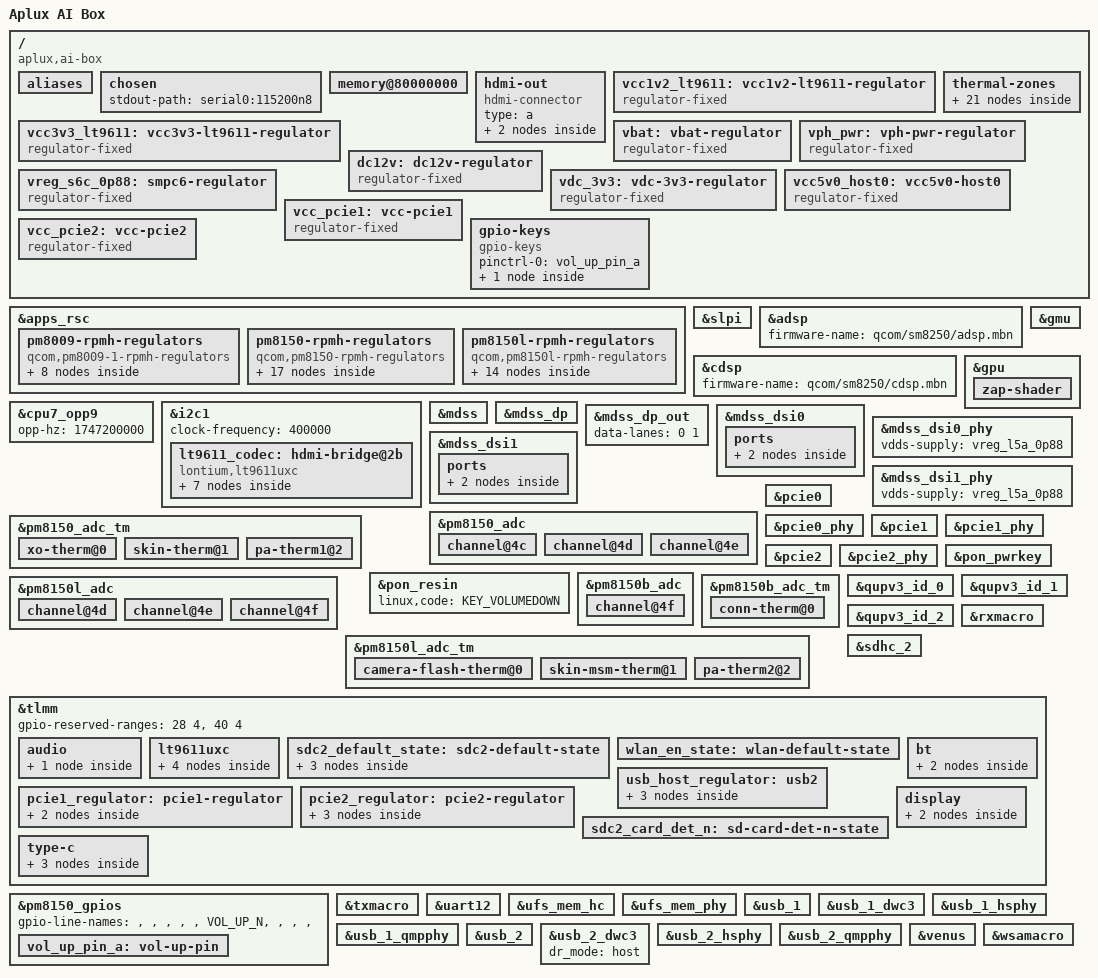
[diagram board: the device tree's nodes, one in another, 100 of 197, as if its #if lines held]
// SPDX-License-Identifier: BSD-3-Clause

/dts-v1/;

#include <dt-bindings/arm/qcom,ids.h>
#include <dt-bindings/regulator/qcom,rpmh-regulator.h>
#include <dt-bindings/phy/phy.h>
#include <dt-bindings/leds/common.h>
#include <dt-bindings/pinctrl/qcom,pmic-gpio.h>
#include <dt-bindings/sound/qcom,q6afe.h>
#include <dt-bindings/sound/qcom,q6asm.h>
#include <dt-bindings/gpio/gpio.h>
#include <dt-bindings/usb/pd.h>
#include "sm8250.dtsi"
#include "pm8150.dtsi"
#include "pm8150b.dtsi"
#include "pm8150l.dtsi"
#include "pm8009.dtsi"

#define ENABLE_HDMI 1

/ {
	model = "Aplux AI Box";
	compatible = "aplux,ai-box", "qcom,sm8250";
	qcom,msm-id = <QCOM_ID_SM8250 0x20001>;
	qcom,board-id = <QCOM_BOARD_ID(SBC, 1, 0) 0>;
	chassis-type = "embedded";

	aliases {
		serial0 = &uart12;
		serial1 = &uart6;
		sdhc2 = &sdhc_2;
	};

	chosen {
		stdout-path = "serial0:115200n8";
	};

#ifdef CONFIG_SYS_PROMPT
	memory@80000000 {
		device_type = "memory";
		reg = <0x00000000 0x80000000  0x00000000 0x3B800000>,   // 952MB
			  <0x00000000 0xC0000000  0x00000001 0xC0000000>;   // 7GB
	};
#endif

#if ENABLE_HDMI
	hdmi-out {
		compatible = "hdmi-connector";
		type = "a";

		port {
			hdmi_con: endpoint {
				remote-endpoint = <&lt9611_out>;
			};
		};
	};

	vcc1v2_lt9611: vcc1v2-lt9611-regulator {
		compatible = "regulator-fixed";
		regulator-name = "vcc1v2_lt9611";

		vin-supply = <&vdc_3v3>;
		regulator-min-microvolt = <1200000>;
		regulator-max-microvolt = <1200000>;

		gpio = <&tlmm 11 GPIO_ACTIVE_HIGH>; // verify
		enable-active-high;
		regulator-boot-on;
		regulator-always-on;

		pinctrl-names = "default";
		pinctrl-0 = <&lt9611_1v2_en>;
	};

	vcc3v3_lt9611: vcc3v3-lt9611-regulator {
		compatible = "regulator-fixed";
		regulator-name = "vcc3v3_lt9611";

		vin-supply = <&vdc_3v3>;
		regulator-min-microvolt = <3300000>;
		regulator-max-microvolt = <3300000>;

		gpio = <&tlmm 61 GPIO_ACTIVE_HIGH>; // verify
		enable-active-high;
		regulator-boot-on;
		regulator-always-on;

		pinctrl-names = "default";
		pinctrl-0 = <&lt9611_3v3_en>;
	};
#endif

	thermal-zones {
		camera-thermal {
			thermal-sensors = <&pm8150l_adc_tm 0>;

			trips {
				active-config0 {
					temperature = <125000>;
					hysteresis = <1000>;
					type = "passive";
				};
			};
		};

		conn-thermal {
			thermal-sensors = <&pm8150b_adc_tm 0>;

			trips {
				active-config0 {
					temperature = <125000>;
					hysteresis = <1000>;
					type = "passive";
				};
			};
		};

		mmw-pa1-thermal {
			thermal-sensors = <&pm8150_adc_tm 2>;

			trips {
				active-config0 {
					temperature = <125000>;
					hysteresis = <1000>;
					type = "passive";
				};
			};
		};

		mmw-pa2-thermal {
			thermal-sensors = <&pm8150l_adc_tm 2>;

			trips {
				active-config0 {
					temperature = <125000>;
					hysteresis = <1000>;
					type = "passive";
				};
			};
		};

		skin-msm-thermal {
			thermal-sensors = <&pm8150l_adc_tm 1>;

			trips {
				active-config0 {
					temperature = <125000>;
					hysteresis = <1000>;
					type = "passive";
				};
			};
		};

		skin-thermal {
			thermal-sensors = <&pm8150_adc_tm 1>;

			trips {
				active-config0 {
					temperature = <125000>;
					hysteresis = <1000>;
					type = "passive";
				};
			};
		};

		xo-thermal {
			thermal-sensors = <&pm8150_adc_tm 0>;

			trips {
				active-config0 {
					temperature = <125000>;
					hysteresis = <1000>;
					type = "passive";
				};
			};
		};
	};

	vbat: vbat-regulator {
		compatible = "regulator-fixed";
		regulator-name = "VBAT";
		vin-supply = <&vreg_l11c_3p3>;
		regulator-min-microvolt = <4200000>;
		regulator-max-microvolt = <4200000>;
		regulator-always-on;
	};

	vph_pwr: vph-pwr-regulator {
		compatible = "regulator-fixed";
		regulator-name = "vph_pwr";
		regulator-min-microvolt = <3700000>;
		regulator-max-microvolt = <3700000>;
	};
/*
	vreg_s4a_1p8: pm8150-s4 {
		compatible = "regulator-fixed";
		regulator-name = "vreg_s4a_1p8";

		regulator-min-microvolt = <1800000>;
		regulator-max-microvolt = <1800000>;

		regulator-always-on;
		regulator-boot-on;

		vin-supply = <&vph_pwr>;
	};
*/
	vreg_s6c_0p88: smpc6-regulator {
		compatible = "regulator-fixed";
		regulator-name = "vreg_s6c_0p88";

		regulator-min-microvolt = <880000>;
		regulator-max-microvolt = <880000>;
		regulator-always-on;
		vin-supply = <&vph_pwr>;
	};

	dc12v: dc12v-regulator {
		compatible = "regulator-fixed";
		regulator-name = "DC12V";
		regulator-min-microvolt = <12000000>;
		regulator-max-microvolt = <12000000>;
		regulator-always-on;
	};

	vdc_3v3: vdc-3v3-regulator {
		compatible = "regulator-fixed";
		regulator-name = "vdc_3v3";
		vin-supply = <&dc12v>;
		regulator-min-microvolt = <3300000>;
		regulator-max-microvolt = <3300000>;
		regulator-always-on;
	};

	vcc5v0_host0: vcc5v0-host0 {
		compatible = "regulator-fixed";
		regulator-name = "vcc5v0_host0";

		vin-supply = <&dc12v>;
		regulator-min-microvolt = <5000000>;
		regulator-max-microvolt = <5000000>;

		gpio = <&tlmm 117 GPIO_ACTIVE_HIGH>; // bsp
		enable-active-high;
		regulator-boot-on;
		regulator-always-on;

		pinctrl-names = "default";
		pinctrl-0 = <&usb_host_regulator>;
	};

	vcc_pcie1: vcc-pcie1 {
		compatible = "regulator-fixed";
		regulator-name = "vcc_pcie1";

		vin-supply = <&dc12v>;
		regulator-min-microvolt = <3300000>;
		regulator-max-microvolt = <3300000>;

		gpio = <&tlmm 6 GPIO_ACTIVE_HIGH>; // bsp
		enable-active-high;
		regulator-boot-on;
		regulator-always-on;

		pinctrl-names = "default";
		pinctrl-0 = <&pcie1_regulator>;
	};

	// RTL8111H
	vcc_pcie2: vcc-pcie2 {
		compatible = "regulator-fixed";
		regulator-name = "vcc_pcie2";

		vin-supply = <&dc12v>;
		regulator-min-microvolt = <3300000>;
		regulator-max-microvolt = <3300000>;

		gpio = <&tlmm 111 GPIO_ACTIVE_HIGH>; // verify
		enable-active-high;
		regulator-boot-on;
		regulator-always-on;

		pinctrl-names = "default";
		pinctrl-0 = <&pcie2_regulator>;
	};

	gpio-keys {
		compatible = "gpio-keys";
		pinctrl-0 = <&vol_up_pin_a>;

		key-vol-up {
			label = "Volume Up";
			linux,code = <KEY_VOLUMEUP>;
			gpios = <&pm8150_gpios 6 GPIO_ACTIVE_LOW>; // bsp
		};
	};
};

&apps_rsc {
	pm8009-rpmh-regulators {
		compatible = "qcom,pm8009-1-rpmh-regulators";
		qcom,pmic-id = "f";

		vdd-s1-supply = <&vph_pwr>;
		vdd-s2-supply = <&vph_pwr>;
		vdd-l2-supply = <&vreg_s8c_1p3>;
		vdd-l5-l6-supply = <&vreg_bob>;
		vdd-l7-supply = <&vreg_s4a_1p8>;

		vreg_s1f_1p2: smps1 {
			regulator-name = "vreg_s1f_1p2"; // bsp
			regulator-min-microvolt = <1200000>;
			regulator-max-microvolt = <1200000>;
			regulator-initial-mode = <RPMH_REGULATOR_MODE_AUTO>;
		};

		vreg_s2f_1p1: smps2 {
			regulator-name = "vreg_s2f_1p1"; // bsp
			regulator-min-microvolt = <512000>;
			regulator-max-microvolt = <1100000>;
			regulator-initial-mode = <RPMH_REGULATOR_MODE_AUTO>;
		};

		vreg_l1f_1p1: ldo1 {
			regulator-name = "vreg_l1f_1p1"; // bsp
			regulator-min-microvolt = <1104000>;
			regulator-max-microvolt = <1104000>;
			regulator-initial-mode = <RPMH_REGULATOR_MODE_HPM>;
		};

		vreg_l2f_1p2: ldo2 {
			regulator-name = "vreg_l2f_1p2"; // bsp
			regulator-min-microvolt = <1200000>;
			regulator-max-microvolt = <1200000>;
			regulator-initial-mode = <RPMH_REGULATOR_MODE_HPM>;
		};

		vreg_l3f_1p05: ldo3 {
			regulator-name = "vreg_l3f_1p05"; // bsp
			regulator-min-microvolt = <1056000>;
			regulator-max-microvolt = <1056000>;
			regulator-initial-mode = <RPMH_REGULATOR_MODE_HPM>;
		};

		vreg_l5f_2p85: ldo5 {
			regulator-name = "vreg_l5f_2p85"; // bsp
			regulator-min-microvolt = <2800000>;
			regulator-max-microvolt = <3000000>;
			regulator-initial-mode = <RPMH_REGULATOR_MODE_HPM>;
		};

		vreg_l6f_2p85: ldo6 {
			regulator-name = "vreg_l6f_2p85"; // bsp
			regulator-min-microvolt = <2800000>;
			regulator-max-microvolt = <3000000>;
			regulator-initial-mode = <RPMH_REGULATOR_MODE_HPM>;
		};

		vreg_l7f_1p8: ldo7 {
			regulator-name = "vreg_l7f_1p8"; // bsp
			regulator-min-microvolt = <1800000>;
			regulator-max-microvolt = <1800000>;
			regulator-initial-mode = <RPMH_REGULATOR_MODE_HPM>;
		};
	};

	pm8150-rpmh-regulators {
		compatible = "qcom,pm8150-rpmh-regulators";
		qcom,pmic-id = "a";

		vdd-s1-supply = <&vph_pwr>;
		vdd-s2-supply = <&vph_pwr>;
		vdd-s3-supply = <&vph_pwr>;
		vdd-s4-supply = <&vph_pwr>;
		vdd-s5-supply = <&vph_pwr>;
		vdd-s6-supply = <&vph_pwr>;
		vdd-s7-supply = <&vph_pwr>;
		vdd-s8-supply = <&vph_pwr>;
		vdd-s9-supply = <&vph_pwr>;
		vdd-s10-supply = <&vph_pwr>;
		vdd-l1-l8-l11-supply = <&vreg_s6c_0p88>;
		vdd-l2-l10-supply = <&vreg_bob>;
		vdd-l3-l4-l5-l18-supply = <&vreg_s6a_0p95>;
		vdd-l6-l9-supply = <&vreg_s8c_1p3>;
		vdd-l7-l12-l14-l15-supply = <&vreg_s5a_1p9>;
		vdd-l13-l16-l17-supply = <&vreg_bob>;

		vreg_s4a_1p8: smps4 {
			regulator-name = "vreg_s4a_1p8"; // bsp
			regulator-min-microvolt = <1800000>;
			regulator-max-microvolt = <1920000>;
			regulator-initial-mode = <RPMH_REGULATOR_MODE_HPM>;
		};

		vreg_s5a_1p9: smps5 {
			regulator-name = "vreg_s5a_1p9"; // bsp
			regulator-min-microvolt = <1824000>;
			regulator-max-microvolt = <2040000>;
			regulator-initial-mode = <RPMH_REGULATOR_MODE_HPM>;
		};

		vreg_s6a_0p95: smps6 {
			regulator-name = "vreg_s6a_0p95"; // bsp
			regulator-min-microvolt = <600000>;
			regulator-max-microvolt = <1128000>;
			regulator-initial-mode = <RPMH_REGULATOR_MODE_HPM>;
		};

		vreg_l2a_3p1: ldo2 {
			regulator-name = "vreg_l2a_3p1"; // bsp
			regulator-min-microvolt = <3072000>;
			regulator-max-microvolt = <3072000>;
			regulator-initial-mode = <RPMH_REGULATOR_MODE_HPM>;
		};

		vreg_l3a_0p9: ldo3 {
			regulator-name = "vreg_l3a_0p9"; // bsp
			regulator-min-microvolt = <928000>;
			regulator-max-microvolt = <932000>;
			regulator-initial-mode = <RPMH_REGULATOR_MODE_HPM>;
		};

		vreg_l5a_0p88: ldo5 {
			regulator-name = "vreg_l5a_0p88"; // bsp
			regulator-min-microvolt = <880000>;
			regulator-max-microvolt = <880000>;
			regulator-initial-mode = <RPMH_REGULATOR_MODE_HPM>;
		};

		vreg_l6a_1p2: ldo6 {
			regulator-name = "vreg_l6a_1p2"; // bsp
			regulator-min-microvolt = <1200000>;
			regulator-max-microvolt = <1200000>;
			regulator-initial-mode = <RPMH_REGULATOR_MODE_HPM>;
		};

		vreg_l7a_1p7: ldo7 {
			regulator-name = "vreg_l7a_1p7"; // bsp
			regulator-min-microvolt = <1704000>;
			regulator-max-microvolt = <1800000>;
			regulator-initial-mode = <RPMH_REGULATOR_MODE_HPM>;
		};

		vreg_l9a_1p2: ldo9 {
			regulator-name = "vreg_l9a_1p2"; // bsp
			regulator-min-microvolt = <1200000>;
			regulator-max-microvolt = <1200000>;
			regulator-initial-mode = <RPMH_REGULATOR_MODE_HPM>;
		};

		vreg_l10a_1p8: ldo10 {
			regulator-name = "vreg_l10a_1p8"; // bsp
			regulator-min-microvolt = <1800000>;
			regulator-max-microvolt = <2960000>;
			regulator-initial-mode = <RPMH_REGULATOR_MODE_HPM>;
		};

		vreg_l12a_1p8: ldo12 {
			regulator-name = "vreg_l12a_1p8"; // bsp
			regulator-min-microvolt = <1800000>;
			regulator-max-microvolt = <1800000>;
			regulator-initial-mode = <RPMH_REGULATOR_MODE_HPM>;
		};

		vreg_l13a_ts_3p0: ldo13 {
			regulator-name = "vreg_l13a_ts_3p0"; // bsp
			regulator-min-microvolt = <3008000>;
			regulator-max-microvolt = <3008000>;
			regulator-initial-mode = <RPMH_REGULATOR_MODE_HPM>;
		};

		vreg_l14a_1p8: ldo14 {
			regulator-name = "vreg_l14a_1p8"; // bsp
			regulator-min-microvolt = <1800000>;
			regulator-max-microvolt = <1880000>;
			regulator-initial-mode = <RPMH_REGULATOR_MODE_HPM>;
		};

		vreg_l15a_1p8: ldo15 {
			regulator-name = "vreg_l15a_1p8"; // bsp
			regulator-min-microvolt = <1800000>;
			regulator-max-microvolt = <1800000>;
			regulator-initial-mode = <RPMH_REGULATOR_MODE_HPM>;
		};

		vreg_l16a_3p3: ldo16 {
			regulator-name = "vreg_l16a_3p3"; // bsp
			regulator-min-microvolt = <3024000>;
			regulator-max-microvolt = <3304000>;
			regulator-initial-mode = <RPMH_REGULATOR_MODE_HPM>;
		};

		vreg_l17a_2p96: ldo17 {
			regulator-name = "vreg_l17a_2p96"; // bsp
			regulator-min-microvolt = <2496000>;
			regulator-max-microvolt = <3008000>;
			regulator-initial-mode = <RPMH_REGULATOR_MODE_HPM>;
		};

		vreg_l18a_0p92: ldo18 {
			regulator-name = "vreg_l18a_0p92"; // bsp
			regulator-min-microvolt = <800000>;
			regulator-max-microvolt = <920000>;
			regulator-initial-mode = <RPMH_REGULATOR_MODE_HPM>;
		};
	};

	pm8150l-rpmh-regulators {
		compatible = "qcom,pm8150l-rpmh-regulators";
		qcom,pmic-id = "c";

		vdd-s1-supply = <&vph_pwr>;
		vdd-s2-supply = <&vph_pwr>;
		vdd-s3-supply = <&vph_pwr>;
		vdd-s4-supply = <&vph_pwr>;
		vdd-s5-supply = <&vph_pwr>;
		vdd-s6-supply = <&vph_pwr>;
		vdd-s7-supply = <&vph_pwr>;
		vdd-s8-supply = <&vph_pwr>;
		vdd-l1-l8-supply = <&vreg_s4a_1p8>;
		vdd-l2-l3-supply = <&vreg_s8c_1p3>;
		vdd-l4-l5-l6-supply = <&vreg_bob>;
		vdd-l7-l11-supply = <&vreg_bob>;
		vdd-l9-l10-supply = <&vreg_bob>;
		vdd-bob-supply = <&vph_pwr>;

		vreg_bob: bob {
			regulator-name = "vreg_bob"; // bsp
			regulator-min-microvolt = <3008000>;
			regulator-max-microvolt = <3960000>;
			regulator-initial-mode = <RPMH_REGULATOR_MODE_AUTO>;
		};

		vreg_s7c_1p0: smps7 {
			regulator-name = "vreg_s7c_1p0"; // bsp
			regulator-min-microvolt = <348000>;
			regulator-max-microvolt = <1000000>;
			regulator-initial-mode = <RPMH_REGULATOR_MODE_HPM>;
		};

		vreg_s8c_1p3: smps8 {
			regulator-name = "vreg_s8c_1p3"; // bsp
			regulator-min-microvolt = <1200000>;
			regulator-max-microvolt = <1400000>;
			regulator-initial-mode = <RPMH_REGULATOR_MODE_HPM>;
		};

		vreg_l1c_1p8: ldo1 {
			regulator-name = "vreg_l1c_1p8"; // bsp
			regulator-min-microvolt = <1800000>;
			regulator-max-microvolt = <1800000>;
			regulator-initial-mode = <RPMH_REGULATOR_MODE_HPM>;
		};

		vreg_l2c_1p2: ldo2 {
			regulator-name = "vreg_l2c_1p2"; // bsp
			regulator-min-microvolt = <1200000>;
			regulator-max-microvolt = <1304000>;
			regulator-initial-mode = <RPMH_REGULATOR_MODE_HPM>;
		};

		vreg_l3c_0p8: ldo3 {
			regulator-name = "vreg_l3c_0p8"; // bsp
			regulator-min-microvolt = <800000>;
			regulator-max-microvolt = <1200000>;
			regulator-initial-mode = <RPMH_REGULATOR_MODE_HPM>;
		};

		vreg_l4c_1p8: ldo4 {
			regulator-name = "vreg_l4c_1p8"; // bsp
			regulator-min-microvolt = <1800000>;
			regulator-max-microvolt = <2800000>;
			regulator-initial-mode = <RPMH_REGULATOR_MODE_HPM>;
		};

		vreg_l5c_1p8: ldo5 {
			regulator-name = "vreg_l5c_1p8"; // bsp
			regulator-min-microvolt = <1800000>;
			regulator-max-microvolt = <2800000>;
			regulator-initial-mode = <RPMH_REGULATOR_MODE_HPM>;
		};

		vreg_l6c_2p96: ldo6 {
			regulator-name = "vreg_l6c_2p96"; // bsp
			regulator-min-microvolt = <1800000>;
			regulator-max-microvolt = <2960000>;
			regulator-initial-mode = <RPMH_REGULATOR_MODE_HPM>;
		};

		vreg_l7c_cam_vcm0_2p85: ldo7 {
			regulator-name = "vreg_l7c_cam_vcm0_2p85"; // bsp
			regulator-min-microvolt = <2856000>;
			regulator-max-microvolt = <3104000>;
			regulator-initial-mode = <RPMH_REGULATOR_MODE_HPM>;
		};

		vreg_l8c_1p8: ldo8 {
			regulator-name = "vreg_l8c_1p8"; // bsp
			regulator-min-microvolt = <1800000>;
			regulator-max-microvolt = <1800000>;
			regulator-initial-mode = <RPMH_REGULATOR_MODE_HPM>;
		};

		vreg_l9c_2p96: ldo9 {
			regulator-name = "vreg_l9c_2p96"; // bsp
			regulator-min-microvolt = <2704000>;
			regulator-max-microvolt = <2960000>;
			regulator-initial-mode = <RPMH_REGULATOR_MODE_HPM>;
		};

		vreg_l10c_3p0: ldo10 {
			regulator-name = "vreg_l10c_3p0"; // bsp
			regulator-min-microvolt = <3000000>;
			regulator-max-microvolt = <3312000>;
			regulator-initial-mode = <RPMH_REGULATOR_MODE_HPM>;
		};

		vreg_l11c_3p3: ldo11 {
			regulator-name = "vreg_l11c_3p3"; // bsp
			regulator-min-microvolt = <3104000>;
			regulator-max-microvolt = <3312000>;
			regulator-initial-mode = <RPMH_REGULATOR_MODE_HPM>;
		};
	};
};

&slpi {
	status = "okay";
	firmware-name = "qcom/sm8250/Thundercomm/RB5/slpi.mbn";
};

&adsp {
	status = "okay";
	firmware-name = "qcom/sm8250/adsp.mbn";
};

&cdsp {
	status = "okay";
	firmware-name = "qcom/sm8250/cdsp.mbn";
};

&gmu {
	status = "okay";
};

&cpu7_opp9 {
	opp-hz = /bits/ 64 <1747200000>;
};

&gpu {
	status = "okay";

	zap-shader {
		memory-region = <&gpu_mem>;
		firmware-name = "qcom/sm8250/a650_zap.mbn";
	};
};

#if ENABLE_HDMI
&i2c1 {
	status = "okay";
	clock-frequency = <400000>;

	lt9611_codec: hdmi-bridge@2b {
		compatible = "lontium,lt9611uxc";
		reg = <0x2b>;
		#sound-dai-cells = <1>;

		interrupts-extended = <&tlmm 59 IRQ_TYPE_EDGE_FALLING>; // verify

		reset-gpios = <&tlmm 62 GPIO_ACTIVE_HIGH>; // verify

		vdd-supply = <&vcc1v2_lt9611>;
		vcc-supply = <&vcc3v3_lt9611>;

		pinctrl-names = "default";
		pinctrl-0 = <&lt9611_irq_pin>, <&lt9611_rst_pin>;

		ports {
			#address-cells = <1>;
			#size-cells = <0>;

			port@0 {
				reg = <0>;

				lt9611_a: endpoint {
					remote-endpoint = <&mdss_dsi0_out>;
				};
			};

			port@1 {
				reg = <1>;

				lt9611_b: endpoint {
					remote-endpoint = <&mdss_dsi1_out>;
				};
			};

			port@2 {
				reg = <2>;

				lt9611_out: endpoint {
					remote-endpoint = <&hdmi_con>;
				};
			};
		};
	};
};

&mdss {
	status = "okay";
};

&mdss_dp {
	status = "okay";
};

&mdss_dp_out {
	data-lanes = <0 1>;
};

&mdss_dsi0 {
	status = "okay";
	vdda-supply = <&vreg_l9a_1p2>;

	qcom,dual-dsi-mode;
	qcom,master-dsi;

	ports {
		port@1 {
			endpoint {
				remote-endpoint = <&lt9611_a>;
				data-lanes = <0 1 2 3>;
			};
		};
	};
};

&mdss_dsi0_phy {
	status = "okay";
	vdds-supply = <&vreg_l5a_0p88>;
};

&mdss_dsi1 {
	status = "okay";
	vdda-supply = <&vreg_l9a_1p2>;

	qcom,dual-dsi-mode;

	/* DSI1 is slave, so use DSI0 clocks */
	assigned-clock-parents = <&mdss_dsi0_phy 0>, <&mdss_dsi0_phy 1>;

	ports {
		port@1 {
			endpoint {
				remote-endpoint = <&lt9611_b>;
				data-lanes = <0 1 2 3>;
			};
		};
	};
};

&mdss_dsi1_phy {
	status = "okay";
	vdds-supply = <&vreg_l5a_0p88>;
};
#endif

&pm8150_adc {
	channel@4c {
		reg = <ADC5_XO_THERM_100K_PU>;
		qcom,ratiometric;
		qcom,hw-settle-time = <200>;
		label = "xo_therm";
	};

	channel@4d {
		reg = <ADC5_AMUX_THM1_100K_PU>;
		qcom,ratiometric;
		qcom,hw-settle-time = <200>;
		label = "skin_therm";
	};

	channel@4e {
		reg = <ADC5_AMUX_THM2_100K_PU>;
		qcom,ratiometric;
		qcom,hw-settle-time = <200>;
		label = "pa_therm1";
	};
};

&pm8150_adc_tm {
	status = "okay";

	xo-therm@0 {
		reg = <0>;
		io-channels = <&pm8150_adc ADC5_XO_THERM_100K_PU>;
		qcom,ratiometric;
		qcom,hw-settle-time-us = <200>;
	};

	skin-therm@1 {
		reg = <1>;
		io-channels = <&pm8150_adc ADC5_AMUX_THM1_100K_PU>;
		qcom,ratiometric;
		qcom,hw-settle-time-us = <200>;
	};

	pa-therm1@2 {
		reg = <2>;
		io-channels = <&pm8150_adc ADC5_AMUX_THM2_100K_PU>;
		qcom,ratiometric;
		qcom,hw-settle-time-us = <200>;
	};
};

&pcie0 {
	status = "okay";
};

&pcie0_phy {
	status = "okay";

	vdda-phy-supply = <&vreg_l5a_0p88>;
	vdda-pll-supply = <&vreg_l9a_1p2>;
};

&pcie1 {
	status = "okay";
};

&pcie1_phy {
	status = "okay";

	vdda-phy-supply = <&vreg_l5a_0p88>;
	vdda-pll-supply = <&vreg_l9a_1p2>;
};

// RTL8111H
&pcie2 {
	status = "okay";
};

&pcie2_phy {
	status = "okay";

	vdda-phy-supply = <&vreg_l5a_0p88>;
	vdda-pll-supply = <&vreg_l9a_1p2>;
};

&pon_pwrkey {
	status = "okay";
};

&pon_resin {
	status = "okay";

	linux,code = <KEY_VOLUMEDOWN>;
};

&pm8150b_adc {
	channel@4f {
		reg = <ADC5_AMUX_THM3_100K_PU>;
		qcom,ratiometric;
		qcom,hw-settle-time = <200>;
		label = "conn_therm";
	};
};

&pm8150b_adc_tm {
	status = "okay";

	conn-therm@0 {
		reg = <0>;
		io-channels = <&pm8150b_adc ADC5_AMUX_THM3_100K_PU>;
		qcom,ratiometric;
		qcom,hw-settle-time-us = <200>;
	};
};

&pm8150l_adc {
	channel@4d {
		reg = <ADC5_AMUX_THM1_100K_PU>;
		qcom,ratiometric;
		qcom,hw-settle-time = <200>;
		label = "camera_flash_therm";
	};

	channel@4e {
		reg = <ADC5_AMUX_THM2_100K_PU>;
		qcom,ratiometric;
		qcom,hw-settle-time = <200>;
		label = "skin_msm_therm";
	};

	channel@4f {
		reg = <ADC5_AMUX_THM3_100K_PU>;
		qcom,ratiometric;
		qcom,hw-settle-time = <200>;
		label = "pa_therm2";
	};
};

&pm8150l_adc_tm {
	status = "okay";

	camera-flash-therm@0 {
		reg = <0>;
		io-channels = <&pm8150l_adc ADC5_AMUX_THM1_100K_PU>;
		qcom,ratiometric;
		qcom,hw-settle-time-us = <200>;
	};

	skin-msm-therm@1 {
		reg = <1>;
		io-channels = <&pm8150l_adc ADC5_AMUX_THM2_100K_PU>;
		qcom,ratiometric;
		qcom,hw-settle-time-us = <200>;
	};

	pa-therm2@2 {
		reg = <2>;
		io-channels = <&pm8150l_adc ADC5_AMUX_THM3_100K_PU>;
		qcom,ratiometric;
		qcom,hw-settle-time-us = <200>;
	};
};

&qupv3_id_0 {
	status = "okay";
};

&qupv3_id_1 {
	status = "okay";
};

&qupv3_id_2 {
	status = "okay";
};

&rxmacro {
	status = "okay";
};

&sdhc_2 {
	status = "okay";

	cd-gpios = <&tlmm 77 GPIO_ACTIVE_LOW>; // bsp
	pinctrl-names = "default", "sleep";
	pinctrl-0 = <&sdc2_default_state &sdc2_card_det_n>;
	pinctrl-1 = <&sdc2_sleep_state &sdc2_card_det_n>;
	vmmc-supply = <&vreg_l9c_2p96>;
	vqmmc-supply = <&vreg_l6c_2p96>;
	bus-width = <4>;
	no-sdio;
	no-mmc;
};

&tlmm {
	gpio-reserved-ranges = <28 4>, <40 4>;

	audio {
		audio_active: audio-active {
			pins = "gpio10"; // bsp
			function = "gpio";
			output-high;
		};
	};

#if ENABLE_HDMI
	lt9611uxc {
		lt9611_irq_pin: lt9611-irq-pin {
			pins = "gpio59"; // verify
			function = "gpio";
			bias-disable;
		};

		lt9611_rst_pin: lt9611-rst-pin {
			pins = "gpio62"; // verify
			function = "gpio";
			output-high;
		};

		lt9611_3v3_en: lt9611-3v3-en {
			pins = "gpio61"; // verify
			function = "gpio";
			output-high;
		};

		lt9611_1v2_en: lt9611-1v2-en {
			pins = "gpio11";
			function = "gpio";
			output-high;
		};
	};
#endif

	sdc2_default_state: sdc2-default-state { // bsp
		clk-pins {
			pins = "sdc2_clk";
			drive-strength = <16>;
			bias-disable;
		};

		cmd-pins {
			pins = "sdc2_cmd";
			drive-strength = <16>;
			bias-pull-up;
		};

		data-pins {
			pins = "sdc2_data";
			drive-strength = <16>;
			bias-pull-up;
		};
	};

	wlan_en_state: wlan-default-state {
		pins = "gpio20"; // bsp
		function = "gpio";
		drive-strength = <16>;
		output-low;
		bias-pull-up;
	};

	bt {
		bt_en_state: bt-default-state {
			pins = "gpio21"; // bsp
			function = "gpio";
			drive-strength = <16>;
			output-low;
			bias-pull-up;
		};

		bt_sw_ctrl: bt-sw-ctrl {
			pins = "gpio124"; // bsp
			function = "gpio";
			output-high;
		};
	};

	usb_host_regulator: usb2 {
		vcc5v0_host0_en: vcc5v0-host0-en {
			pins = "gpio117"; // bsp
			function = "gpio";
			output-high;
		};

		vcc3v3_host0_en: vcc3v3-host0-en {
			pins = "gpio112"; // bsp
			function = "gpio";
			output-high;
		};

		vcc1v2_host0_en: vcc1v2-host0-en {
			pins = "gpio118"; // bsp
			function = "gpio";
			output-high;
		};
	};

	pcie1_regulator:pcie1-regulator {
		pcie1_en_1: pcie1-en-1 {
			pins = "gpio6"; // bsp
			function = "gpio";
			output-high;
		};
		pcie1_en_2: pcie1-en-2 {
			pins = "gpio48"; // bsp
			function = "gpio";
			output-high;
		};
	};

	pcie2_regulator:pcie2-regulator {
		vcc3v3_pcie2_en: vcc3v3-pcie2-en {
			pins = "gpio111"; // verify
			function = "gpio";
			output-high;
		};
		pcie2_en_1: pcie2-en-1 {
			pins = "gpio7"; // verify
			function = "gpio";
			output-high;
		};
		pcie2_en_2: pcie2-en-2 {
			pins = "gpio89"; // verify
			function = "gpio";
			output-high;
		};
	};

	sdc2_card_det_n: sd-card-det-n-state {
		pins = "gpio77"; // bsp
		function = "gpio";
		bias-pull-up;
		drive-strength = <2>;
	};

	display {
		vcc2v8_display_panel_avdd_en: vcc2v8-display-panel-avdd-en {
			pins = "gpio23"; // bsp
			function = "gpio";
			output-high;
		};

		display_panel_panel_active_1: display-panel-panel-active-1 {
			pins = "gpio75"; // bsp
			function = "gpio";
			output-high;
		};

		// display_panel_panel_active_2: display-panel-panel-active-2 {
		// 	pins = "gpio60"; // bsp
		// 	function = "gpio";
		// 	output-high;
		// };
	};

	type-c {
		aux_en_gpio: aux-en-gpio {
			pins = "gpio9"; // bsp
			function = "gpio";
			bias-pull-up;
			drive-strength = <2>;
		};

		aux_sel_gpio: aux-sel-gpio {
			pins = "gpio8"; // bsp
			function = "gpio";
			bias-pull-up;
			drive-strength = <2>;
		};

		usbplug_cc_gpio: usbplug-cc-gpio {
			pins = "gpio65"; // bsp
			function = "gpio";
			bias-pull-up;
			drive-strength = <2>;
		};
	};
};

&pm8150_gpios {
	gpio-line-names =
		"",
		"",
		"",
		"",
		"",
		"VOL_UP_N",
		"",
		"",
		"",
		"";

	vol_up_pin_a: vol-up-pin {
		pins = "gpio6"; // bsp
		function = "normal";
		input-enable;
		bias-pull-up;
		qcom,drive-strength = <PMIC_GPIO_STRENGTH_NO>;
	};
};

&txmacro {
	status = "okay";
};

&uart12 {
	status = "okay";
};

&ufs_mem_hc {
	status = "okay";

	vcc-supply = <&vreg_l17a_2p96>;
	vcc-max-microamp = <800000>;
	vccq-supply = <&vreg_l6a_1p2>;
	vccq-max-microamp = <800000>;
	vccq2-supply = <&vreg_s4a_1p8>;
	vccq2-max-microamp = <800000>;
};

&ufs_mem_phy {
	status = "okay";

	vdda-phy-supply = <&vreg_l5a_0p88>;
	vdda-pll-supply = <&vreg_l9a_1p2>;
};

&usb_1 {
	status = "okay";
};

&usb_1_dwc3 {
	// dr_mode = "peripheral";
	dr_mode = "otg";
	usb-role-switch;
};

&usb_1_hsphy {
	status = "okay";

	vdda-pll-supply = <&vreg_l5a_0p88>;
	vdda33-supply = <&vreg_l2a_3p1>;
	vdda18-supply = <&vreg_l12a_1p8>;
};

&usb_1_qmpphy {
	status = "okay";

	vdda-phy-supply = <&vreg_l9a_1p2>;
	vdda-pll-supply = <&vreg_l18a_0p92>;
};

&usb_2 {
	status = "okay";
};

&usb_2_dwc3 {
	dr_mode = "host";
};

&usb_2_hsphy {
	status = "okay";

	vdda-pll-supply = <&vreg_l5a_0p88>;
	vdda18-supply = <&vreg_l12a_1p8>;
	vdda33-supply = <&vreg_l2a_3p1>;
};

&usb_2_qmpphy {
	status = "okay";

	vdda-phy-supply = <&vreg_l9a_1p2>;
	vdda-pll-supply = <&vreg_l18a_0p92>;
};

&venus {
	status = "okay";
};

&wsamacro {
	status = "okay";
};
